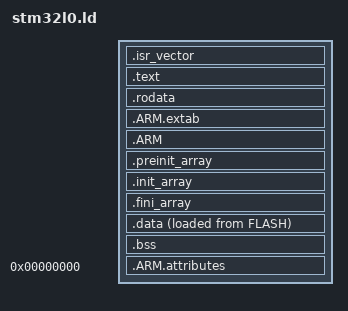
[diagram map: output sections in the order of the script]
/* Entry Point */
ENTRY(Reset_Handler)

/* Highest address of the user mode stack */
_estack = ORIGIN(RAM) + LENGTH(RAM)-1;

/* Program Headers: define explicit permissions */
PHDRS
{
  text PT_LOAD FLAGS(4);   /* R E */
  data PT_LOAD FLAGS(6);   /* R W */
}

/* Define output sections */
SECTIONS
{
  /* The startup code (R E) */
  .isr_vector :
  {
    isr_vector_address = .;
    . = ALIGN(4);
    KEEP(*(.isr_vector))
    . = ALIGN(4);
  } >FLASH :text

  /* Code section (R E) */
  .text :
  {
    . = ALIGN(4);
    *(.text)
    *(.text*)
    *(.glue_7)
    *(.glue_7t)
    *(.eh_frame)
    KEEP(*(.init))
    KEEP(*(.fini))
    . = ALIGN(4);
    _etext = .;
  } >FLASH :text

  /* Constants section (R E) */
  .rodata :
  {
    . = ALIGN(4);
    *(.rodata)
    *(.rodata*)
  } >FLASH :text

  .ARM.extab : { *(.ARM.extab* .gnu.linkonce.armextab.*) } >FLASH :text
  .ARM :
  {
    __exidx_start = .;
    *(.ARM.exidx*)
    __exidx_end = .;
  } >FLASH :text

  .preinit_array :
  {
    PROVIDE_HIDDEN (__preinit_array_start = .);
    KEEP(*(.preinit_array*))
    PROVIDE_HIDDEN (__preinit_array_end = .);
  } >FLASH :text

  .init_array :
  {
    PROVIDE_HIDDEN (__init_array_start = .);
    KEEP(*(SORT(.init_array.*)))
    KEEP(*(.init_array*))
    PROVIDE_HIDDEN (__init_array_end = .);
  } >FLASH :text

  .fini_array :
  {
    PROVIDE_HIDDEN (__fini_array_start = .);
    KEEP(*(SORT(.fini_array.*)))
    KEEP(*(.fini_array*))
    PROVIDE_HIDDEN (__fini_array_end = .);
  } >FLASH :text

  /* Used by startup to initialize data */
  _sidata = LOADADDR(.data);

  /* Data section (R W) */
  .data :
  {
    . = ALIGN(4);
    _sdata = .;
    *(.data)
    *(.data*)
    . = ALIGN(4);
    _edata = .;
  } >RAM AT> FLASH :data

  /* BSS section (R W) */
  .bss (NOLOAD) :
  {
    _sbss = .;
    __bss_start__ = _sbss;
    *(.bss)
    *(.bss*)
    *(COMMON)
    . = ALIGN(4);
    _ebss = .;
    __bss_end__ = _ebss;
  } >RAM :data

  /* Remove info from standard libs */
  /DISCARD/ :
  {
    libc.a ( * )
    libm.a ( * )
    libgcc.a ( * )
  }

  .ARM.attributes 0 : { *(.ARM.attributes) }
}
